# S32M24x register map
Vendor: NXP Semiconductors; File version: 1.3
CPU: CM4 r0p1, little endian, MPU, FPU, VTOR, 4 interrupt priority bits
Registers are 32-bit, read-write, reset 0x0 unless marked. A register's access mark holds for its fields unless they carry their own. Offsets are from the block's base; [hi:lo] are bit positions; {n}, {i} and the like mark numbered series; 'fields as' and 'values as' point back to an identical list.

## PORTA — PORT
Base 0x40049000
Same registers: PORTB 0x4004A000, PORTC 0x4004B000, PORTD 0x4004C000, PORTE 0x4004D000
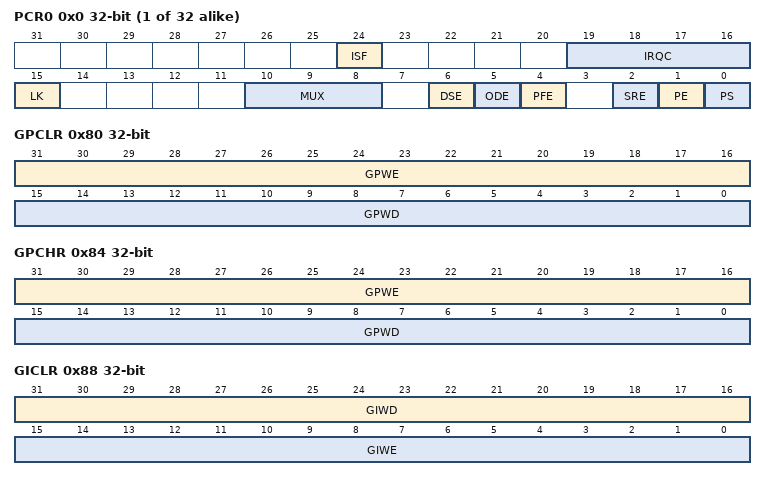
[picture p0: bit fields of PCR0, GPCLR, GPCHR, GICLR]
{0x0+4i} PCR{i} (i=0..31) — Pin Control Register {i}
  [24] ISF write-1-clears — Interrupt Status Flag
    0=Configured interrupt is not detected; 1=Configured interrupt is detected. If the pin is configured to generate a DMA request, then the corresponding flag will be cleared automatically at the completion of the requested DMA transfer. Otherwise, the flag remains set until a logic 1 is written to the flag. If the pin is configured for a level sensitive interrupt and the pin remains asserted, then the flag is set again immediately after it is cleared.
  [19:16] IRQC — Interrupt Configuration
    0=Interrupt Status Flag (ISF) is disabled; 1=ISF flag and DMA request on rising edge; 2=ISF flag and DMA request on falling edge; 3=ISF flag and DMA request on either edge; 5=Flag sets on rising edge; 6=Flag sets on falling edge; 7=Flag sets on either edge; 8=ISF flag and Interrupt when logic 0; 9=ISF flag and Interrupt on rising-edge; 10=ISF flag and Interrupt on falling-edge; 11=ISF flag and Interrupt on either edge; 12=ISF flag and Interrupt when logic 1; 13=Enable active high trigger output, flag is disabled. [The trigger output goes to the trigger mux, which allows pins to trigger other peripherals (configurable polarity; 1 pin per port; if multiple pins are configured, then they are ORed together to create the trigger)]; 14=Enable active low trigger output, flag is disabled
  [15] LK — Lock Register
    0=Pin Control Register is not locked; 1=Pin Control Register is locked and cannot be updated until the next system reset
  [10:8] MUX — Pin Mux Control
    0=Pin disabled (Alternative 0) (analog); 1=Alternative 1 (GPIO); {v}=Alternative {v} (chip-specific) (v=2..7)
  [6] DSE — Drive Strength Enable
    0=Low drive strength is configured on the corresponding pin, if pin is configured as a digital output; 1=High drive strength is configured on the corresponding pin, if pin is configured as a digital output
  [5] ODE — Open Drain Enable
    0=Open drain output is disabled on the corresponding pin; 1=Open drain output is enabled on the corresponding pin, if the pin is configured as a digital output
  [4] PFE — Passive Filter Enable
    0=Passive input filter is disabled on the corresponding pin; 1=Passive input filter is enabled on the corresponding pin, if the pin is configured as a digital input. Refer to the device data sheet for filter characteristics.
  [2] SRE — Slew Rate Enable
    0=Fast slew rate is configured on the corresponding pin, if the pin is configured as a digital output; 1=Slow slew rate is configured on the corresponding pin, if the pin is configured as a digital output
  [1] PE — Pull Enable
    0=Internal pull resistor is not enabled on the corresponding pin; 1=Internal pull resistor is enabled on the corresponding pin, if the pin is configured as a digital input
  [0] PS — Pull Select
    0=Internal pulldown resistor is enabled on the corresponding pin, if the corresponding PE field is set; 1=Internal pullup resistor is enabled on the corresponding pin, if the corresponding PE field is set
0x80 GPCLR — Global Pin Control Low Register
  [31:16] GPWE — Global Pin Write Enable
  [15:0] GPWD — Global Pin Write Data
0x84 GPCHR — Global Pin Control High Register
  fields as GPCLR
0x88 GICLR — Global Interrupt Control Low Register
  [31:16] GIWD — Global Interrupt Write Data
  [15:0] GIWE — Global Interrupt Write Enable
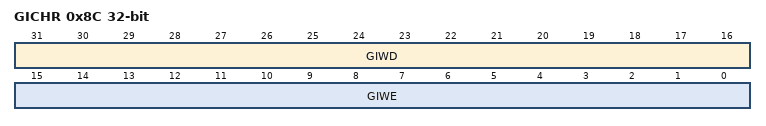
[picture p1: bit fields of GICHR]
0x8C GICHR — Global Interrupt Control High Register
  fields as GICLR
0xA0 ISFR write-1-clears — Interrupt Status Flag Register
  [31:0] ISF write-1-clears — Interrupt Status Flag
0xC0 DFER — Digital Filter Enable Register
  [31:0] DFE — Digital Filter Enable
0xC4 DFCR — Digital Filter Clock Register
  [0] CS — Clock Source
    0=Digital filters are clocked by the bus clock; 1=Digital filters are clocked by the PMC 1kHz LPO clock
0xC8 DFWR — Digital Filter Width Register
  [4:0] FILT — Filter Length
